# STM32MP21_CM33 register map
File version: 0.4
CPU: CM33 r0p1, little endian, MPU, FPU, vendor SysTick, 8 interrupt priority bits
Registers are 32-bit, read-write, reset 0x0 unless marked. A register's access mark holds for its fields unless they carry their own. Offsets are from the block's base; [hi:lo] are bit positions; {n}, {i} and the like mark numbered series; 'fields as' and 'values as' point back to an identical list.

## FDCAN1 (part 2 of 2) — FDCAN address block description
Base 0x402D0000
Same registers: FDCAN2 0x402E0000, FDCAN1_S 0x502D0000, FDCAN2_S 0x502E0000
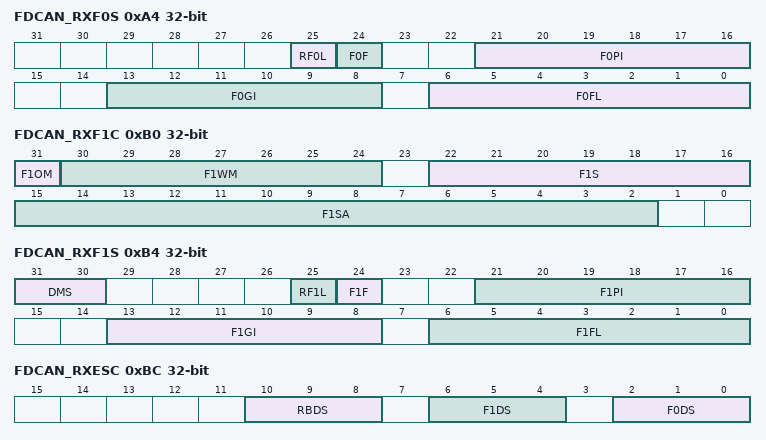
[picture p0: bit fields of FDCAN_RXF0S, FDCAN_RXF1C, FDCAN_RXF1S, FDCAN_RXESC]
0xA4 FDCAN_RXF0S — FDCAN Rx FIFO 0 status register
  [25] RF0L — Rx FIFO 0 message lost This bit is a copy of interrupt flag FDCAN_IR.RF0L. When FDCAN_IR.RF0L is reset, this bit is also reset.
    0=No Rx FIFO 0 message lost; 1=Rx FIFO 0 message lost, also set after write attempt to Rx FIFO 0 of size 0
  [24] F0F — Rx FIFO 0 full
    0=Rx FIFO 0 not full; 1=Rx FIFO 0 full
  [21:16] F0PI — Rx FIFO 0 put index Rx FIFO 0 write index pointer, range 0 to 63.
  [13:8] F0GI — Rx FIFO 0 get index Rx FIFO 0 read index pointer, range 0 to 63.
  [6:0] F0FL — Rx FIFO 0 fill level Number of elements stored in Rx FIFO 0, range 0 to 64.
0xA8 FDCAN_RXF0A — FDCAN Rx FIFO 0 acknowledge register
  [5:0] F0AI — Rx FIFO 0 acknowledge index After the user has read a message or a sequence of messages from Rx FIFO 0 it has to write the buffer index of the last element read from Rx FIFO 0 to F0AI. This sets the Rx FIFO 0 get index FDCAN_RXF0S.F0GI to F0AI + 1 and update the FIFO 0 fill level FDCAN_RXF0S.F0FL.
0xAC FDCAN_RXBC — FDCAN Rx buffer configuration register
  [15:2] RBSA — Rx buffer start address Configures the start address of the Rx buffers section in the message RAM (32-bit word address). Also used to reference debug messages A, B, C. These are write-protected bits, write access is possible only when bit CCE and bit INIT of FDCAN_CCCR register are set to 1.
0xB0 FDCAN_RXF1C — FDCAN Rx FIFO 1 configuration register
  [31] F1OM — FIFO 1 operation mode FIFO 1 can be operated in blocking or in overwrite mode.
    0=FIFO 1 blocking mode; 1=FIFO 1 overwrite mode
  [30:24] F1WM — Rx FIFO 1 watermark 1-64: Level for Rx FIFO 1 watermark interrupt (FDCAN_IR.RF1W) superior64: Watermark interrupt disabled. These are write-protected bits, write access is possible only when bit CCE and bit INIT of FDCAN_CCCR register are set to 1.
    0=Watermark interrupt disabled
  [22:16] F1S — Rx FIFO 1 size 1-64: Number of Rx FIFO 1 elements superior64: Values greater than 64 are interpreted as 64 The Rx FIFO 1 elements are indexed from 0 to F1S - 1. These are write-protected bits, write access is possible only when bit CCE and bit INIT of FDCAN_CCCR register are set to 1.
    0=No Rx FIFO 1
  [15:2] F1SA — Rx FIFO 1 start address start address of Rx FIFO 1 in message RAM (32-bit word address, see Figure 1033). These are write-protected bits, write access is possible only when bit CCE and bit INIT of FDCAN_CCCR register are set to 1.
0xB4 FDCAN_RXF1S ro — FDCAN Rx FIFO 1 status register
  [31:30] DMS — Debug message status
    0=Idle state, wait for reception of debug messages; 1=Debug message A received; 2=Debug messages A, B received; 3=Debug messages A, B, C received
  [25] RF1L — Rx FIFO 1 message lost This bit is a copy of interrupt flag FDCAN_IR.RF1L. When FDCAN_IR.RF1L is reset, this bit is also reset.
    0=No Rx FIFO 1 message lost; 1=Rx FIFO 1 message lost, also set after write attempt to Rx FIFO 1 of size 0
  [24] F1F — Rx FIFO 1 full
    0=Rx FIFO 1 not full; 1=Rx FIFO 1 full
  [21:16] F1PI — Rx FIFO 1 put index Rx FIFO 1 write index pointer, range 0 to 63.
  [13:8] F1GI — Rx FIFO 1 get index Rx FIFO 1 read index pointer, range 0 to 63.
  [6:0] F1FL — Rx FIFO 1 fill level Number of elements stored in Rx FIFO 1, range 0 to 64
0xB8 FDCAN_RXF1A — FDCAN Rx FIFO 1 acknowledge register
  [5:0] F1AI — Rx FIFO 1 acknowledge index After the user has read a message or a sequence of messages from Rx FIFO 1 it has to write the buffer index of the last element read from Rx FIFO 1 to F1AI. This sets the Rx FIFO 1 get index FDCAN_RXF1S.F1GI. to F1AI + 1 and update the FIFO 1 fill level FDCAN_RXF1S.F1FL.
0xBC FDCAN_RXESC ro — FDCAN Rx buffer element size configuration register
  [all] fields
    0=8-byte data field; 1=12-byte data field; 2=16-byte data field; 3=20-byte data field; 4=24-byte data field; 5=32-byte data field; 6=48-byte data field; 7=64-byte data field
  [10:8] RBDS — Rx buffer data field size
  [6:4] F1DS — Rx FIFO 0 data field size
  [2:0] F0DS — Rx FIFO 1 data field size
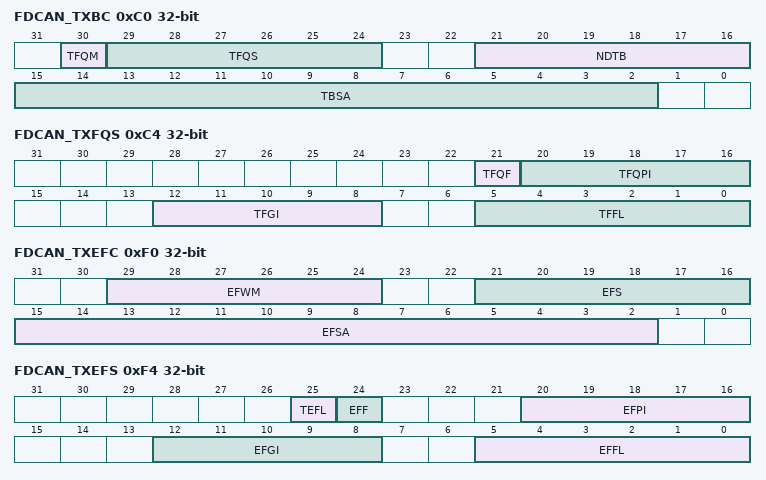
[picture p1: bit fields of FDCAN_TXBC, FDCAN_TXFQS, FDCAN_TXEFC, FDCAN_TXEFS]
0xC0 FDCAN_TXBC — FDCAN Tx buffer configuration register
  [30] TFQM — Tx FIFO/queue mode These are write-protected bits, write access is possible only when bit CCE and bit INIT of FDCAN_CCCR register are set to 1.
    0=Tx FIFO operation; 1=Tx queue operation
  [29:24] TFQS — Transmit FIFO/queue size 1-32: Number of Tx buffers used for Tx FIFO/queue superior32: Values greater than 32 are interpreted as 32. These are write-protected bits, write access is possible only when bit CCE and bit INIT of FDCAN_CCCR register are set to 1.
    0=No Tx FIFO/queue
  [21:16] NDTB — Number of dedicated transmit buffers 1-32: Number of dedicated Tx buffers superior32: Values greater than 32 are interpreted as 32. These are write-protected bits, write access is possible only when bit CCE and bit INIT of FDCAN_CCCR register are set to 1.
    0=No dedicated Tx buffers
  [15:2] TBSA — Tx buffers start address Start address of Tx buffers section in message RAM (32-bit word address, see Figure 1033). These are write-protected bits, write access is possible only when bit CCE and bit INIT of FDCAN_CCCR register are set to 1.
0xC4 FDCAN_TXFQS ro — FDCAN Tx FIFO/queue status register
  [21] TFQF — Tx FIFO/queue full 0 Tx FIFO/queue not full 1 Tx FIFO/queue full
  [20:16] TFQPI — Tx FIFO/queue put index Tx FIFO/queue write index pointer, range 0 to 31
  [12:8] TFGI — Tx FIFO get index. Tx FIFO read index pointer, range 0 to 31. Read as 0 when Tx queue operation is configured (FDCAN_TXBC.TFQM = 1)
  [5:0] TFFL — Tx FIFO free level Number of consecutive free Tx FIFO elements starting from TFGI, range 0 to 32. Read as 0 when Tx queue operation is configured (FDCAN_TXBC.TFQM = 1).
0xC8 FDCAN_TXESC ro — FDCAN Tx buffer element size configuration register
  [2:0] TBDS — Tx buffer data Field size:
    values as the fields of FDCAN_RXESC
0xCC FDCAN_TXBRP ro — FDCAN Tx buffer request pending register
  [31:0] TRP — Transmission request pending Each Tx buffer has its own transmission request pending bit. The bits are set via register FDCAN_TXBAR. The bits are reset after a requested transmission has completed or has been canceled via register FDCAN_TXBCR. FDCAN_TXBRP bits are set only for those Tx buffers configured via FDCAN_TXBC. After an FDCAN_TXBRP bit has been set, a Tx scan (see Filtering for Debug messages) is started to check for the pending Tx request with the highest priority (Tx buffer with lowest message ID). A cancellation request resets the corresponding transmission request pending bit of register FDCAN_TXBRP. In case a transmission has already been started when a cancellation is requested, this is done at the end of the transmission, regardless whether the transmission was successful or not. The cancellation request bits are reset directly after the corresponding FDCAN_TXBRP bit has been reset. After a cancellation has been requested, a finished cancellation is signaled via FDCAN_TXBCF after successful transmission together with the corresponding FDCAN_TXBTO bit when the transmission has not yet been started at the point of cancellation when the transmission has been aborted due to lost arbitration when an error occurred during frame transmission In DAR mode all transmissions are automatically canceled if they are not successful. The corresponding FDCAN_TXBCF bit is set for all unsuccessful transmissions.
    0=No transmission request pending; 1=Transmission request pending
0xD0 FDCAN_TXBAR — FDCAN Tx buffer add request register
  [31:0] AR — Add request Each Tx buffer has its own add request bit. Writing a 1 sets the corresponding add request bit; writing a 0 has no impact. This enables the user to set transmission requests for multiple Tx buffers with one write to FDCAN_TXBAR. FDCAN_TXBAR bits are set only for those Tx buffers configured via FDCAN_TXBC. When no Tx scan is running, the bits are reset immediately, else the bits remain set until the Tx scan process has completed.
    0=No transmission request added; 1=Transmission requested added
0xD4 FDCAN_TXBCR — FDCAN Tx buffer cancellation request register
  [31:0] CR — Cancellation request Each Tx buffer has its own cancellation request bit. Writing a 1 sets the corresponding cancellation request bit; writing a 0 has no impact. This enables the user to set cancellation requests for multiple Tx buffers with one write to FDCAN_TXBCR. FDCAN_TXBCR bits are set only for those Tx buffers configured via FDCAN_TXBC. The bits remain set until the corresponding FDCAN_TXBRP bit is reset.
    0=No cancellation pending; 1=Cancellation pending
0xD8 FDCAN_TXBTO ro — FDCAN Tx buffer transmission occurred register
  [31:0] TO — Transmission occurred Each Tx buffer has its own transmission occurred bit. The bits are set when the corresponding FDCAN_TXBRP bit is cleared after a successful transmission. The bits are reset when a new transmission is requested by writing a 1 to the corresponding bit of register FDCAN_TXBAR.
    0=No transmission occurred; 1=Transmission occurred
0xDC FDCAN_TXBCF ro — FDCAN Tx buffer cancellation finished register
  [31:0] CF — Cancellation finished Each Tx buffer has its own cancellation finished bit. The bits are set when the corresponding FDCAN_TXBRP bit is cleared after a cancellation was requested via FDCAN_TXBCR. In case the corresponding FDCAN_TXBRP bit was not set at the point of cancellation, CF is set immediately. The bits are reset when a new transmission is requested by writing a 1 to the corresponding bit of register FDCAN_TXBAR.
    0=No transmit buffer cancellation; 1=Transmit buffer cancellation finished
0xE0 FDCAN_TXBTIE — FDCAN Tx buffer transmission interrupt enable register
  [31:0] TIE — Transmission interrupt enable Each Tx buffer has its own transmission interrupt enable bit.
    0=Transmission interrupt disabled; 1=Transmission interrupt enable
0xE4 FDCAN_TXBCIE — FDCAN Tx buffer cancellation finished interrupt enable register
  [31:0] CFIE — Cancellation finished interrupt enable Each Tx buffer has its own cancellation finished interrupt enable bit.
    0=Cancellation finished interrupt disabled; 1=Cancellation finished interrupt enabled
0xF0 FDCAN_TXEFC — FDCAN Tx event FIFO configuration register
  [29:24] EFWM — Event FIFO watermark 1-32: Level for Tx event FIFO watermark interrupt (FDCAN_IR.TEFW) superior32: Watermark interrupt disabled These are write-protected bits, write access is possible only when bit CCE and bit INIT of FDCAN_CCCR register are set to 1.
    0=Watermark interrupt disabled
  [21:16] EFS — Event FIFO size. 1-32: Number of Tx event FIFO elements superior32: Values greater than 32 are interpreted as 32 The Tx event FIFO elements are indexed from 0 to EFS-1. These are write-protected bits, write access is possible only when bit CCE and bit INIT of FDCAN_CCCR register are set to 1.
    0=Tx event FIFO disabled
  [15:2] EFSA — Event FIFO start address Start address of Tx event FIFO in message RAM (32-bit word address, see Figure 1033). These are write-protected bits, write access is possible only when bit CCE and bit INIT of FDCAN_CCCR register are set to 1.
0xF4 FDCAN_TXEFS ro — FDCAN Tx event FIFO status register
  [25] TEFL — Tx event FIFO element lost This bit is a copy of interrupt flag FDCAN_IR.TEFL. When FDCAN_IR.TEFL is reset, this bit is also reset. 0 No Tx event FIFO element lost 1 Tx event FIFO element lost, also set after write attempt to Tx event FIFO of size 0.
  [24] EFF — Event FIFO full
    0=Tx event FIFO not full; 1=Tx event FIFO full
  [20:16] EFPI — Event FIFO put index Tx event FIFO write index pointer, range 0 to 31.
  [12:8] EFGI — Event FIFO get index Tx event FIFO read index pointer, range 0 to 31.
  [5:0] EFFL — Event FIFO fill level Number of elements stored in Tx event FIFO, range 0 to 31.
0xF8 FDCAN_TXEFA — FDCAN Tx event FIFO acknowledge register
  [4:0] EFAI — Event FIFO acknowledge index After the user has read an element or a sequence of elements from the Tx event FIFO, it must write the index of the last element read from Tx event FIFO to EFAI. This sets the Tx event FIFO get index FDCAN_TXEFS.EFGI to EFAI + 1 and update the FIFO 0 fill level FDCAN_TXEFS.EFFL.
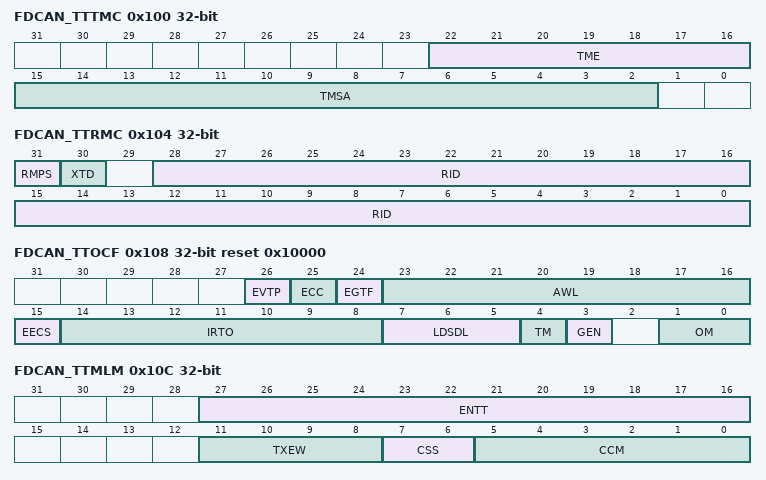
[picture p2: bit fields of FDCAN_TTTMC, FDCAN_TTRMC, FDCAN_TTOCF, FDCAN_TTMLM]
0x100 FDCAN_TTTMC — FDCAN TT trigger memory configuration register
  [22:16] TME — Trigger memory elements 1-64: Number of trigger memory elements superior64: Values greater than 64 are interpreted as 64 These are write-protected bits, write access is possible only when bit CCE and bit INIT of FDCAN_CCCR register are set to 1.
    0=No trigger memory
  [15:2] TMSA — Trigger memory start address. Start address of trigger memory in message RAM (32-bit word address, see Figure 1033). These are write-protected bits, write access is possible only when bit CCE and bit INIT of FDCAN_CCCR register are set to 1.
0x104 FDCAN_TTRMC — FDCAN TT reference message configuration register
  [31] RMPS — Reference message payload select Ignored in case of time slaves. Message marker MM, Event FIFO control EFC, Data length code DLC, Data Bytes DB (level 1: bytes 2-8, level 0, 2: bytes 5-8) These are write-protected bits, write access is possible only when bit CCE and bit INIT of FDCAN_CCCR register are set to 1.
    0=Reference message has no additional payload; 1=The following elements are taken from Tx buffer 0:
  [30] XTD — Extended identifier These are write-protected bits, write access is possible only when bit CCE and bit INIT of FDCAN_CCCR register are set to 1.
    0=11-bit standard identifier; 1=29-bit extended identifier
  [28:0] RID — Reference identifier. Identifier transmitted with reference message and used for reference message filtering. Standard or extended reference identifier depending on bit XTD. A standard identifier must be written to ID[28:18]. These are write-protected bits, write access is possible only when bit CCE and bit INIT of FDCAN_CCCR register are set to 1.
0x108 FDCAN_TTOCF reset 0x10000 — FDCAN TT operation configuration register
  [26] EVTP — Event trigger polarity. These are write-protected bits, write access is possible only when bit CCE and bit INIT of FDCAN_CCCR register are set to 1.
    0=Rising edge trigger; 1=Falling edge trigger
  [25] ECC — Enable clock calibration. These are write-protected bits, write access is possible only when bit CCE and bit INIT of FDCAN_CCCR register are set to 1.
    0=Automatic clock calibration in FDCAN level 0, 2 is disabled; 1=Automatic clock calibration in FDCAN level 0, 2 is enabled
  [24] EGTF — Enable global time filtering. These are write-protected bits, write access is possible only when bit CCE and bit INIT of FDCAN_CCCR register are set to 1.
    0=Global time filtering in FDCAN level 0, 2 is disabled; 1=Global time filtering in FDCAN level 0, 2 is enabled
  [23:16] AWL — Application watchdog limit. The application watchdog can be disabled by programming AWL to 0x00. 0x00 to FF: Maximum time after which the application has to serve the application watchdog. The application watchdog is incremented once each 256 NTUs. These are write-protected bits, write access is possible only when bit CCE and bit INIT of FDCAN_CCCR register are set to 1.
  [15] EECS — Enable external clock synchronization If enabled, TUR configuration (FDCAN_TURCF.NCL only) may be updated during FDCAN operation. These are write-protected bits, write access is possible only when bit CCE and bit INIT of FDCAN_CCCR register are set to 1.
    0=External clock synchronization in FDCAN level 0, 2 disabled; 1=External clock synchronization in FDCAN level 0, 2 enabled
  [14:8] IRTO — Initial reference trigger offset. 0x00 to 7F Positive offset, range from 0 to 127 These are write-protected bits, write access is possible only when bit CCE and bit INIT of FDCAN_CCCR register are set to 1.
  [7:5] LDSDL — LD of synchronization deviation limit. The synchronization deviation limit SDL is configured by its dual logarithm LDSDL with SDL = 2 * (LDSDL + 5). SDL is comprised between 32 and 4096. It should not exceed the clock tolerance given by the CAN bit timing configuration. These are write-protected bits, write access is possible only when bit CCE and bit INIT of FDCAN_CCCR register are set to 1.
  [4] TM — Time master. These are write-protected bits, write access is possible only when bit CCE and bit INIT of FDCAN_CCCR register are set to 1.
    0=Time master function disabled; 1=Potential time master
  [3] GEN — Gap enable. These are write-protected bits, write access is possible only when bit CCE and bit INIT of FDCAN_CCCR register are set to 1.
    0=Strictly time-triggered operation; 1=External event-synchronized time-triggered operation
  [1:0] OM — Operation mode. These are write-protected bits, write access is possible only when bit CCE and bit INIT of FDCAN_CCCR register are set to 1.
    0=Event-driven CAN communication, default; 1=TTCAN level 1; 2=TTCAN level 2; 3=TTCAN level 0
0x10C FDCAN_TTMLM — FDCAN TT matrix limits register
  [27:16] ENTT — Expected number of Tx triggers 0x000 to FFF Expected number of Tx triggers in one matrix cycle. These are write-protected bits, write access is possible only when bit CCE and bit INIT of FDCAN_CCCR register are set to 1.
  [11:8] TXEW — Tx enable window 0x0 to F Length of Tx enable window, 1-16 NTU cycles These are write-protected bits, write access is possible only when bit CCE and bit INIT of FDCAN_CCCR register are set to 1.
  [7:6] CSS — Cycle start synchronization Enables sync pulse output. These are write-protected bits, write access is possible only when bit CCE and bit INIT of FDCAN_CCCR register are set to 1.
    0=No sync pulse; 1=Sync pulse at start of basic cycle; 2=Sync pulse at start of matrix cycle
  [5:0] CCM — Cycle count Max Others: Reserved These are write-protected bits, write access is possible only when bit CCE and bit INIT of FDCAN_CCCR register are set to 1.
    0=1 basic cycle per matrix cycle; 1=2 basic cycles per matrix cycle; 3=4 basic cycles per matrix cycle; 7=8 basic cycles per matrix cycle; 15=16 basic cycles per matrix cycle; 31=32 basic cycles per matrix cycle; 63=64 basic cycles per matrix cycle
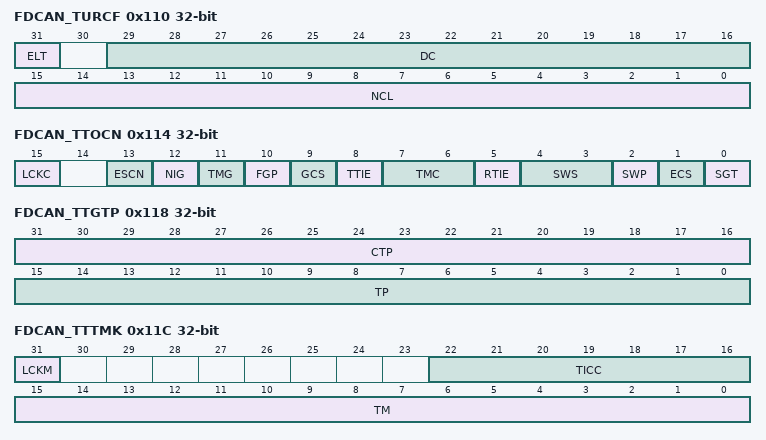
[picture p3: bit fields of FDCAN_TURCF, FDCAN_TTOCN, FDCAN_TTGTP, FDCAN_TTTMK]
0x110 FDCAN_TURCF — FDCAN TUR configuration register
  [31] ELT — Enable local time. These are write-protected bits, write access is possible only when bit CCE and bit INIT of FDCAN_CCCR register are set to 1. Note: The local time is started by setting ELT, it remains active until ELT is reset or until the next hardware reset. FDCAN_TURCF.DC is locked when FDCAN_TURCF.ELT = 1. If ELT is written to 0, the readable value stays at 1 until the new value has been synchronized into the CAN clock domain. During this time write access to the other bits of the register is locked.
    0=Local time is stopped, default; 1=Local time is enabled
  [29:16] DC — Denominator configuration. 0x0001 to 0x3FFF: Denominator configuration These are write-protected bits, write access is possible only when bit CCE and bit INIT of FDCAN_CCCR register are set to 1.
    0=Illegal value
  [15:0] NCL — Numerator configuration low. Write access to the TUR numerator configuration low is only possible during configuration with FDCAN_TURCF.ELT = 0 or if FDCAN_TTOCF.EECS (external clock synchronization enabled) is set. When a new value for NCL is written outside TT configuration mode, the new value takes effect when FDCAN_TTOST.WECS is cleared to 0. NCL is locked FDCAN_TTOST.WECS is 1. 0x0000 to FFFF Numerator configuration low These are write-protected bits, write access is possible only when bit CCE and bit INIT of FDCAN_CCCR register are set to 1.
0x114 FDCAN_TTOCN — FDCAN TT operation control register
  [15] LCKC ro — TT operation control register locked. Set by a write access to register FDCAN_TTOCN. Reset when the updated configuration has been synchronized into the CAN clock domain.
    0=Write access to FDCAN_TTOCN enabled; 1=Write access to FDCAN_TTOCN locked
  [13] ESCN — External synchronization control If enabled the FDCAN synchronizes its cycle time phase to an external event signaled by a rising edge at event trigger pin (see Section 82.4.17: Synchronization to external time schedule).
    0=External synchronization disabled; 1=External synchronization enabled
  [12] NIG — Next is gap. This bit can be set only when the FDCAN is the actual time master and when it is configured for external event-synchronized time-triggered operation (FDCAN_TTOCF.GEN = 1)
    0=No action, reset by reception of any reference message; 1=Transmit next reference message with Next_is_Gap = 1
  [11] TMG — Time mark gap.
    0=Reset by each reference message; 1=Next reference message started when register time mark interrupt FDCAN_TTIR.RTMI is activated
  [10] FGP — Finish gap. Set by the CPU, reset by each reference message
    0=No reference message requested; 1=Application requested start of reference message
  [9] GCS — Gap control select
    0=Gap control independent from event trigger; 1=Gap control by input event trigger pin
  [8] TTIE — Trigger time mark interrupt pulse enable External time mark events are configured by trigger memory element TMEX. A trigger time mark interrupt pulse is generated when the trigger memory element becomes active, and the FDCAN is in synchronization state In_Schedule or In_Gap.
    0=Trigger time mark interrupt output fdcan1_tmp for more than one instance and fdcan_tmp if only one instance disabled; 1=Trigger time mark interrupt output fdcan1_tmp for more than one instance and fdcan_tmp if only one instance enabled
  [7:6] TMC — Register time mark compare. Note: When changing the time mark reference (cycle, local, global time), it is recommended to first write TMC = 00, then reconfigure FDCAN_TTTMK, and finally set FDCAN_TMC to the intended time reference.
    0=No register time mark interrupt generated; 1=Register time mark interrupt if time mark = cycle time; 2=Register time mark interrupt if time mark = local time; 3=Register time mark interrupt if time mark = global time
  [5] RTIE — Register time mark interrupt pulse enable. Register time mark interrupts are configured by register FDCAN_TTTMK. A register time mark interrupt pulse with the length of one fdcan_tq_ck period is generated when time referenced by FDCAN_TTOCN.TMC (cycle, local, or global) is equal to FDCAN_TTTMK.TM, independently from the synchronization state.
    0=Register time mark interrupt output disabled; 1=Register time mark interrupt output enabled
  [4:3] SWS — Stop watch source.
    0=Stop watch disabled; 1=Actual value of cycle time is copied to FDCAN_TTCPT.SWV; 2=Actual value of local time is copied to FDCAN_TTCPT.SWV; 3=Actual value of global time is copied to FDCAN_TTCPT.SWV
  [2] SWP — Stop watch polarity.
    0=Rising edge trigger; 1=Falling edge trigger
  [1] ECS — External clock synchronization. Writing a 1 to ECS sets FDCAN_TTOST.WECS if the node is the actual time master. ECS is reset after one APB clock period. The external clock synchronization takes effect at the start of the next basic cycle.
  [0] SGT — Set global time. Writing a 1 to SGT sets FDCAN_TTOST.WGDT if the node is the actual time master. SGT is reset after one APB clock period. The global time preset takes effect when the node transmits the next reference message with the Master_Ref_Mark modified by the preset value written to FDCAN_TTGTP.
0x118 FDCAN_TTGTP — FDCAN TT global time preset register
  [31:16] CTP — Cycle time target phase CTP is write-protected while FDCAN_TTOCN.ESCN or FDCAN_TTOST.SPL are set (see Section 82.4.17: Synchronization to external time schedule). 0x0000 to FFFF defines the target value of cycle time when a rising edge of event trigger is expected
  [15:0] TP — Time preset TP is write-protected while FDCAN_TTOST.WGTD is set. 0x0000 to 7FFF next master reference mark = master reference mark + TP 0x8000 reserved 0x8001 FFFF Next master reference mark = master reference mark - (0x10000 - TP).
0x11C FDCAN_TTTMK — FDCAN TT time mark register
  [31] LCKM ro — TT time mark register locked Always set by a write access to registers FDCAN_TTOCN. Set by write access to register FDCAN_TTTMK when FDCAN_TTOCN.TMC 00. Reset when the registers have been synchronized into the CAN clock domain.
    0=Write access to FDCAN_TTTMK enabled; 1=Write access to FDCAN_TTTMK locked
  [22:16] TICC — Time mark cycle code Cycle count for which the time mark is valid. 0b000000x valid for all cycles 0b000001c valid every second cycle at cycle count mod2 = c 0b00001cc valid every fourth cycle at cycle count mod4 = cc 0b0001ccc valid every eighth cycle at cycle count mod8 = ccc 0b001cccc valid every sixteenth cycle at cycle count mod16 = cccc 0b01ccccc valid every thirty-second cycle at cycle count mod32 = ccccc 0b1cccccc valid every sixty-fourth cycle at cycle count mod64 = cccccc
  [15:0] TM — Time mark 0x0000 to FFFF time mark
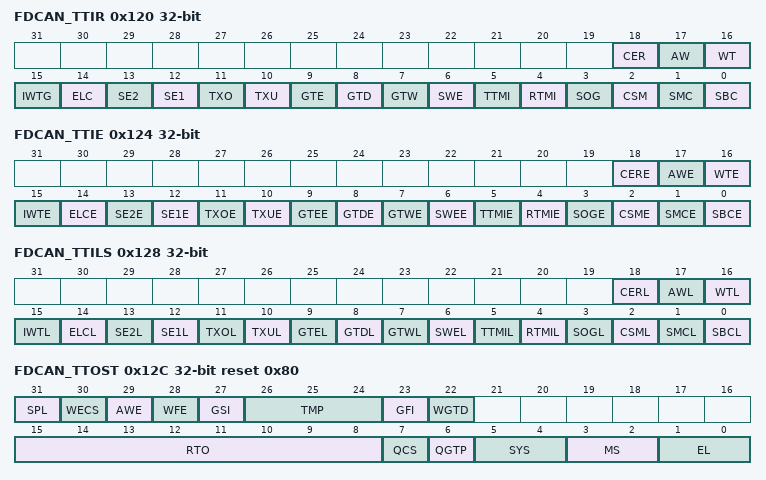
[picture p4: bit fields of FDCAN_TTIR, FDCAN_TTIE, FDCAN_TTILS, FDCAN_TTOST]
0x120 FDCAN_TTIR — FDCAN TT interrupt register
  [18] CER — Configuration error Trigger out of order.
    0=No error found in trigger list; 1=Error found in trigger list
  [17] AW — Application watchdog
    0=Application watchdog served in time; 1=Application watchdog not served in time
  [16] WT — Watch trigger
    0=No missing reference message; 1=Missing reference message (level 0: cycle time 0xFF00)
  [15] IWTG — Initialization watch trigger The initialization is restarted by resetting IWT. 0 No missing reference message during system startup 1 No system startup due to missing reference message
  [14] ELC — Error level changed Not set when error level changed during initialization.
    0=No change in error level; 1=Error level changed
  [13] SE2 — Scheduling error 2
    0=No scheduling error 2; 1=Scheduling error 2 occurred
  [12] SE1 — Scheduling error 1
    0=No scheduling error 1; 1=Scheduling error 1 occurred
  [11] TXO — Tx count overflow
    0=Number of Tx trigger as expected; 1=More Tx trigger than expected in one cycle
  [10] TXU — Tx count underflow
    0=Number of Tx trigger as expected; 1=Less Tx trigger than expected in one cycle
  [9] GTE — Global time error Synchronization deviation SD exceeds limit specified by FDCAN_TTOCF.LDSDL, TTCAN level 0, 2 only.
    0=Synchronization deviation within limit; 1=Synchronization deviation exceeded limit
  [8] GTD — Global time discontinuity
    0=No discontinuity of global time; 1=Discontinuity of global time
  [7] GTW — Global time wrap
    0=No global time wrap occurred; 1=Global time wrap from 0xFFFF to 0x0000 occurred
  [6] SWE — Stop watch event
    0=No rising/falling edge at stop watch trigger pin detected; 1=Rising/falling edge at stop watch trigger pin detected
  [5] TTMI — Trigger time mark event internal Internal time mark events are configured by trigger memory element TMIN (see Section 82.4.23). Set when the trigger memory element becomes active, and the FDCAN is in synchronization state In_Gap or In_Schedule.
    0=Time mark not reached; 1=Time mark reached (level 0: cycle time FDCAN_TTOCF.RTO x 0x200)
  [4] RTMI — Register time mark interrupt Set when time referenced by TTOCN.TMC (cycle, local, or global) is equal to FDCAN_TTTMK.TM, independently from the synchronization state.
    0=Time mark not reached; 1=Time mark reached
  [3] SOG — Start of gap 0 No reference message seen with Next_is_Gap bit set 1 Reference message with Next_is_Gap bit set becomes valid
  [2] CSM — Change of synchronization mode also set when FDCAN_TTOST.SPL is reset
    0=No change in master to slave relation or schedule synchronization; 1=Master to slave relation or schedule synchronization changed,
  [1] SMC — Start of matrix cycle
    0=No matrix cycle started since bit has been reset; 1=Matrix cycle started
  [0] SBC — Start of basic cycle
    0=No basic cycle started since bit has been reset; 1=Basic cycle started
0x124 FDCAN_TTIE — FDCAN TT interrupt enable register
  [all] fields
    0=TT interrupt disabled; 1=TT interrupt enabled
  [18] CERE — Configuration error interrupt enable
  [17] AWE — Application watchdog interrupt enable
  [16] WTE — Watch trigger interrupt enable
  [15] IWTE — Initialization watch trigger interrupt enable
  [14] ELCE — Change error level interrupt enable
  [13] SE2E — Scheduling error 2 interrupt enable
  [12] SE1E — Scheduling error 1 interrupt enable
  [11] TXOE — Tx count overflow interrupt enable
  [10] TXUE — Tx count underflow interrupt enable
  [9] GTEE — Global time error interrupt enable
  [8] GTDE — Global time discontinuity interrupt enable
  [7] GTWE — Global time wrap interrupt enable
  [6] SWEE — Stop watch event interrupt enable
  [5] TTMIE — Trigger time mark event internal interrupt enable
  [4] RTMIE — Register time mark interrupt enable
  [3] SOGE — Start of gap interrupt enable
  [2] CSME — Change of synchronization mode interrupt enable
  [1] SMCE — Start of matrix cycle interrupt enable
  [0] SBCE — Start of basic cycle interrupt enable
0x128 FDCAN_TTILS — FDCAN TT interrupt line select register
  [all] fields
    0=TT interrupt assigned to interrupt line 0; 1=TT interrupt assigned to interrupt line 1
  [18] CERL — Configuration error interrupt line
  [17] AWL — Application watchdog interrupt line
  [16] WTL — Watch trigger interrupt line
  [15] IWTL — Initialization watch trigger interrupt line
  [14] ELCL — Change error level interrupt line
  [13] SE2L — Scheduling error 2 interrupt line
  [12] SE1L — Scheduling error 1 interrupt line
  [11] TXOL — Tx count overflow interrupt line
  [10] TXUL — Tx count underflow interrupt line
  [9] GTEL — Global time error interrupt line
  [8] GTDL — Global time discontinuity interrupt line
  [7] GTWL — Global time wrap interrupt line
  [6] SWEL — Stop watch event interrupt line
  [5] TTMIL — Trigger time mark event internal interrupt line
  [4] RTMIL — Register time mark interrupt line
  [3] SOGL — Start of gap interrupt line
  [2] CSML — Change of synchronization mode interrupt line
  [1] SMCL — Start of matrix cycle interrupt line
  [0] SBCL — Start of basic cycle interrupt line
0x12C FDCAN_TTOST ro reset 0x80 — FDCAN TT operation status register
  [31] SPL — Schedule phase lock The bit is valid only when external synchronization is enabled (FDCAN_TTOCN.ESCN = 1). In this case it signals that the difference between cycle time configured by FDCAN_TTGTP.CTP and the cycle time at the rising edge at event trigger pin is less than or equal to 9 NTU (see Section 82.4.17: Synchronization to external time schedule).
    0=Phase outside range; 1=Phase inside range
  [30] WECS — Wait for external clock synchronization.
    0=No external clock synchronization pending; 1=Node waits for external clock synchronization to take effect. The bit is reset at the start of the next basic cycle.
  [29] AWE — Application watchdog event The application watchdog is served by reading FDCAN_TTOST. When the watchdog is not served in time, bit AWE is set, all FDCAN communication is stopped, and the FDCAN is set into bus monitoring mode.
    0=Application watchdog served in time; 1=Failed to serve application watchdog in time
  [28] WFE — Wait for event
    0=No gap announced, reset by a reference message with Next_is_Gap = 0; 1=Reference message with Next_is_Gap = 1 received
  [27] GSI — Gap started indicator
    0=No gap in schedule, reset by each reference message and for all time slaves; 1=Gap time after basic cycle has started
  [26:24] TMP — Time master priority 0x0-7 Priority of actual time master
  [23] GFI — Gap finished indicator Set when the CPU writes FDCAN_TTOCN.FGP, or by a time mark interrupt if TMG = 1, or via input pin (event trigger) if FDCAN_TTOCN.GCS = 1. Not set by Ref_Trigger_Gap or when Gap is finished by another node sending a reference message.
    0=Reset at the end of each reference message; 1=Gap finished by FDCAN
  [22] WGTD — Wait for global time discontinuity
    0=No global time preset pending; 1=Node waits for the global time preset to take effect. The bit is reset when the node has transmitted a reference message with Disc_Bit = 1 or after it received a reference message.
  [15:8] RTO — Reference trigger offset The reference trigger offset value is a signed integer with a range from -127 (0x81) to 127 (0x7F). There is no notification when the lower limit of-127 is reached. In case the FDCAN becomes time master (MS[1:0] = 11), the reset of RTO is delayed due to synchronization between user and CAN clock domain. For time slaves the value configured by FDCAN_TTOCF.IRTO is read. 0x00-FF Actual reference trigger offset value
  [7] QCS — Quality of clock speed Only relevant in TTCAN level 0 and level 2, otherwise fixed to 1.
    0=Local clock speed not synchronized to time master clock speed; 1=Synchronization deviation less than or eqaul SDL
  [6] QGTP — Quality of global time phase Only relevant in TTCAN level 0 and level 2, otherwise fixed to 0.
    0=Global time not valid; 1=Global time in phase with time master
  [5:4] SYS — Synchronization state
    0=Out of Synchronization; 1=Synchronizing to FDCAN communication; 2=Schedule suspended by gap (In_Gap); 3=Synchronized to schedule (In_Schedule)
  [3:2] MS — Master state
    0=Master_Off, no master properties relevant; 1=Operating as time Slave; 2=Operating as backup time master; 3=Operating as current time master
  [1:0] EL — Error level
    0=Severity 0 - No error; 1=Severity 1 - Warning; 2=Severity 2 - error; 3=Severity 3 - Severe error
0x130 FDCAN_TURNA ro — FDCAN TUR numerator actual register
  [17:0] NAV — Numerator actual value 0x0F000 to 20FFF: actual numerator value
    0xEFFF=illegal value; 0x21000=illegal value
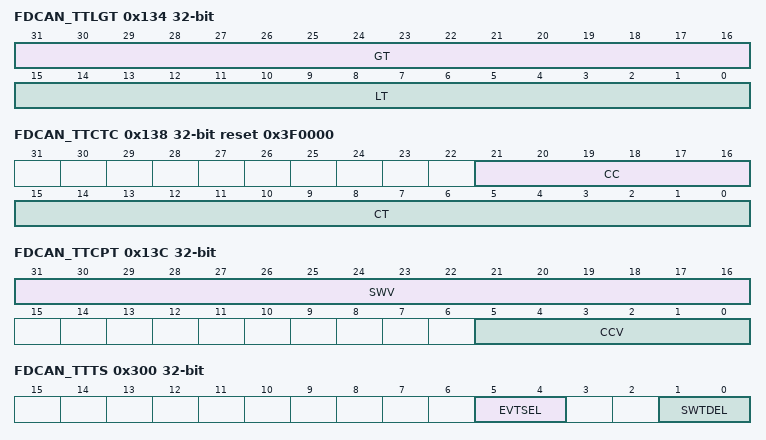
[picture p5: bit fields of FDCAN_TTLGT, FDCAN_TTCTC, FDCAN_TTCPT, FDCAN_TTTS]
0x134 FDCAN_TTLGT ro — FDCAN TT local and global time register
  [31:16] GT — Global time Non-fractional part of the sum of the node local time and its local offset (see Section 82.4.12). 0x0000 to FFFF Global time value of FDCAN network
  [15:0] LT — Local time Non-fractional part of local time, incremented once each local NTU (see Section 82.4.12). 0x0000 to FFFF Local time value of FDCAN node
0x138 FDCAN_TTCTC ro reset 0x3F0000 — FDCAN TT cycle time and count register
  [21:16] CC — Cycle count 0x00 to 3F Number of actual basic cycle in the system matrix
  [15:0] CT — Cycle time Non-fractional part of the difference of the node local time and Ref_Mark (see Section 82.4.12). 0x0000 to FFFF: cycle time value of FDCAN basic cycle
0x13C FDCAN_TTCPT ro — FDCAN TT capture time register
  [31:16] SWV — Stop watch value On a rising / falling edge (as configured via FDCAN_TTOCN.SWP) at the stop watch trigger pin, when FDCAN_TTOCN.SWS] is different from 00 and FDCAN_TTIR.SWE is 0, the actual time value as selected by FDCAN_TTOCN.SWS (cycle, local, global) is copied to SWV and TFDCAN_TIR.SWE is set to 1.Capturing of the next stop watch value is enabled by resetting FDCAN_TTIR.SWE. 0x0000 to FFFF Captured stop watch value
  [5:0] CCV — Cycle count value Cycle count value captured together with SWV. 0x00 to 3F: captured cycle count value
0x140 FDCAN_TTCSM ro — FDCAN TT cycle sync mark register
  [15:0] CSM — Cycle sync mark The cycle sync mark is measured in cycle time. It is updated when the reference message becomes valid and retains its value until the next reference message becomes valid. 0x0000 to FFFF Captured cycle time
0x300 FDCAN_TTTS — FDCAN TT trigger select register
  [5:4] EVTSEL — Event trigger input selection These bits are used to select the input to be used as event trigger
    {v}=fdcan1_evt{v} (v=0..3)
  [1:0] SWTDEL — Stop watch trigger input selection These bits are used to select the input to be used as stop watch trigger
    {v}=fdcan1_swt{v} (v=0..3)
